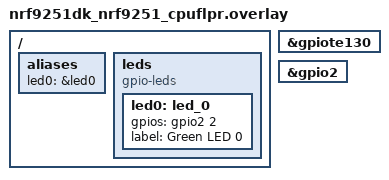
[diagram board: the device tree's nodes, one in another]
/*
 * Copyright (c) 2026 Nordic Semiconductor ASA
 *
 * SPDX-License-Identifier: LicenseRef-Nordic-5-Clause
 */

/ {
	aliases {
		led0 = &led0;
	};

	leds {
		compatible = "gpio-leds";

		led0: led_0 {
			gpios = <&gpio2 2 GPIO_ACTIVE_HIGH>;
			label = "Green LED 0";
		};
	};
};

&gpiote130 {
	status = "okay";
};

&gpio2 {
	status = "okay";
};
